# STM32L4x6_v1r1 register map
File version: 1.1
CPU: CM4 r0p1, little endian, MPU, FPU, 4 interrupt priority bits
Registers are 32-bit, read-write, reset 0x0 unless marked. A register's access mark holds for its fields unless they carry their own. Offsets are from the block's base; [hi:lo] are bit positions; {n}, {i} and the like mark numbered series; 'fields as' and 'values as' point back to an identical list.

## OPAMP — Operational amplifiers
Base 0x40007800
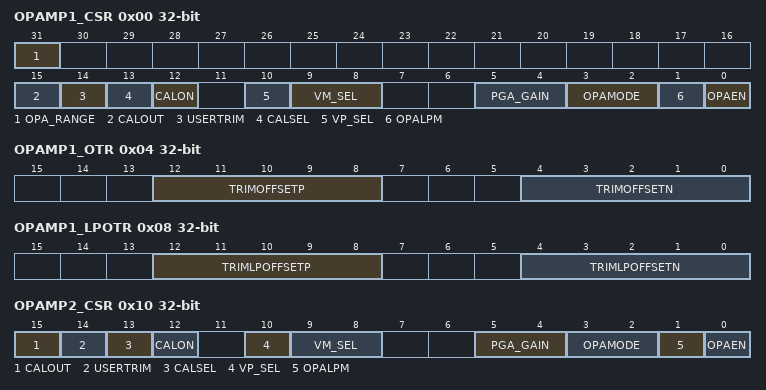
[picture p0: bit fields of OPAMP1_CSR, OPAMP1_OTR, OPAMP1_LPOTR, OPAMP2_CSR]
0x00 OPAMP1_CSR — OPAMP1 control/status register
  [31] OPA_RANGE — Operational amplifier power supply range for stability
  [15] CALOUT — Operational amplifier calibration output
  [14] USERTRIM — allows to switch from AOP offset trimmed values to AOP offset
  [13] CALSEL — Calibration selection
  [12] CALON — Calibration mode enabled
  [10] VP_SEL — Non inverted input selection
  [9:8] VM_SEL — Inverting input selection
  [5:4] PGA_GAIN — Operational amplifier Programmable amplifier gain value
  [3:2] OPAMODE — Operational amplifier PGA mode
  [1] OPALPM — Operational amplifier Low Power Mode
  [0] OPAEN — Operational amplifier Enable
0x04 OPAMP1_OTR — OPAMP1 offset trimming register in normal mode
  [12:8] TRIMOFFSETP — Trim for PMOS differential pairs
  [4:0] TRIMOFFSETN — Trim for NMOS differential pairs
0x08 OPAMP1_LPOTR — OPAMP1 offset trimming register in low-power mode
  [12:8] TRIMLPOFFSETP — Trim for PMOS differential pairs
  [4:0] TRIMLPOFFSETN — Trim for NMOS differential pairs
0x10 OPAMP2_CSR — OPAMP2 control/status register
  [15] CALOUT — Operational amplifier calibration output
  [14] USERTRIM — allows to switch from AOP offset trimmed values to AOP offset
  [13] CALSEL — Calibration selection
  [12] CALON — Calibration mode enabled
  [10] VP_SEL — Non inverted input selection
  [9:8] VM_SEL — Inverting input selection
  [5:4] PGA_GAIN — Operational amplifier Programmable amplifier gain value
  [3:2] OPAMODE — Operational amplifier PGA mode
  [1] OPALPM — Operational amplifier Low Power Mode
  [0] OPAEN — Operational amplifier Enable
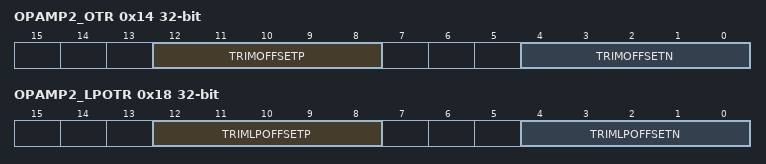
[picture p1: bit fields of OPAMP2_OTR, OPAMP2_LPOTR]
0x14 OPAMP2_OTR — OPAMP2 offset trimming register in normal mode
  fields as OPAMP1_OTR
0x18 OPAMP2_LPOTR — OPAMP2 offset trimming register in low-power mode
  fields as OPAMP1_LPOTR

## FMC — Flexible memory controller
Base 0xA0000000
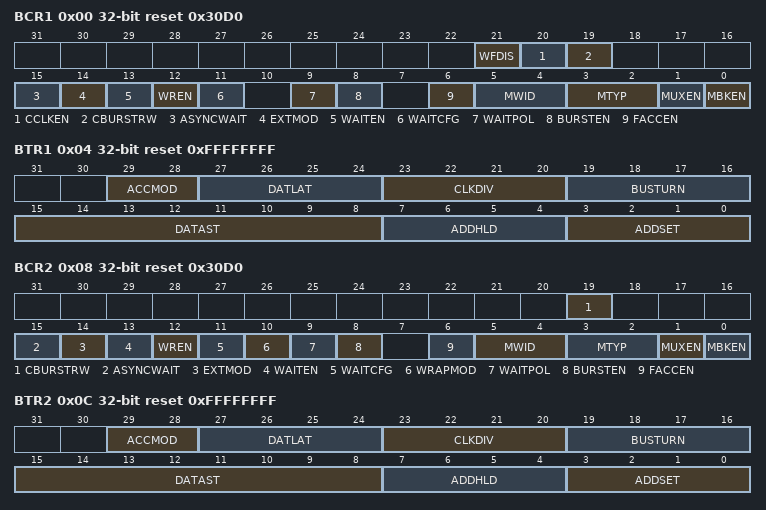
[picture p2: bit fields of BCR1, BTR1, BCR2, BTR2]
0x00 BCR1 reset 0x30D0 — SRAM/NOR-Flash chip-select control register 1
  [21] WFDIS — Write FIFO Disable
  [20] CCLKEN
  [19] CBURSTRW
  [15] ASYNCWAIT
  [14] EXTMOD
  [13] WAITEN
  [12] WREN
  [11] WAITCFG
  [9] WAITPOL
  [8] BURSTEN
  [6] FACCEN
  [5:4] MWID
  [3:2] MTYP
  [1] MUXEN
  [0] MBKEN
0x04 BTR1 reset 0xFFFFFFFF — SRAM/NOR-Flash chip-select timing register 1
  [29:28] ACCMOD, [27:24] DATLAT, [23:20] CLKDIV, [19:16] BUSTURN, [15:8] DATAST, [7:4] ADDHLD, [3:0] ADDSET
0x08 BCR2 reset 0x30D0 — SRAM/NOR-Flash chip-select control register 2
  [19] CBURSTRW, [15] ASYNCWAIT, [14] EXTMOD, [13] WAITEN, [12] WREN, [11] WAITCFG, [10] WRAPMOD, [9] WAITPOL, [8] BURSTEN, [6] FACCEN, [5:4] MWID, [3:2] MTYP, [1] MUXEN, [0] MBKEN
0x0C BTR2 reset 0xFFFFFFFF — SRAM/NOR-Flash chip-select timing register 2
  fields as BTR1
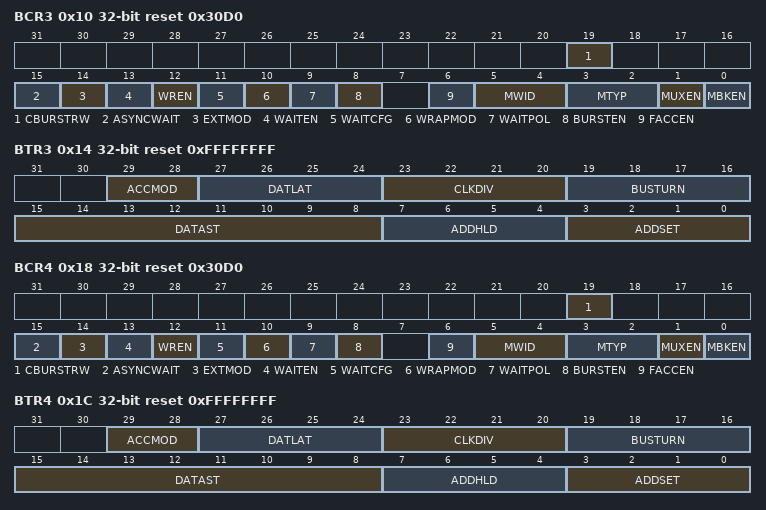
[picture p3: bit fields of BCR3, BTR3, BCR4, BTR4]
0x10 BCR3 reset 0x30D0 — SRAM/NOR-Flash chip-select control register 3
  fields as BCR2
0x14 BTR3 reset 0xFFFFFFFF — SRAM/NOR-Flash chip-select timing register 3
  fields as BTR1
0x18 BCR4 reset 0x30D0 — SRAM/NOR-Flash chip-select control register 4
  fields as BCR2
0x1C BTR4 reset 0xFFFFFFFF — SRAM/NOR-Flash chip-select timing register 4
  fields as BTR1
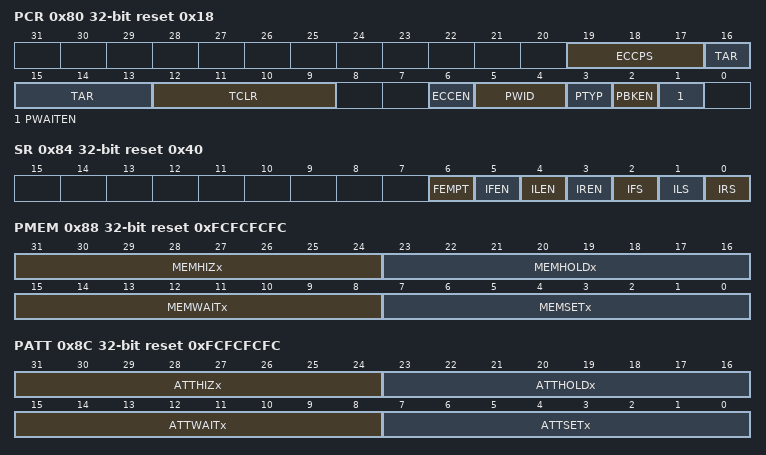
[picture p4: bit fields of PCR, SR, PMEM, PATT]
0x80 PCR reset 0x18 — PC Card/NAND Flash control register 3
  [19:17] ECCPS, [16:13] TAR, [12:9] TCLR, [6] ECCEN, [5:4] PWID, [3] PTYP, [2] PBKEN, [1] PWAITEN
0x84 SR access per field reset 0x40 — FIFO status and interrupt register 3
  [6] FEMPT ro, [5] IFEN rw, [4] ILEN rw, [3] IREN rw, [2] IFS rw, [1] ILS rw, [0] IRS rw
0x88 PMEM reset 0xFCFCFCFC — Common memory space timing register 3
  [31:24] MEMHIZx, [23:16] MEMHOLDx, [15:8] MEMWAITx, [7:0] MEMSETx
0x8C PATT reset 0xFCFCFCFC — Attribute memory space timing register 3
  [31:24] ATTHIZx, [23:16] ATTHOLDx, [15:8] ATTWAITx, [7:0] ATTSETx
0x94 ECCR ro — ECC result register 3
  [31:0] ECCx
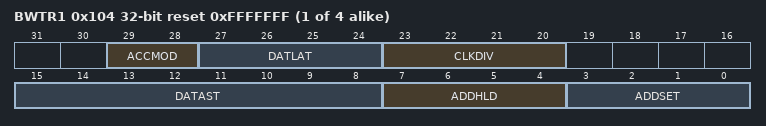
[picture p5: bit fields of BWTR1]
{0xFC+8i} BWTR{i} reset 0xFFFFFFF (i=1..4) — SRAM/NOR-Flash write timing registers {i}
  [29:28] ACCMOD, [27:24] DATLAT, [23:20] CLKDIV, [15:8] DATAST, [7:4] ADDHLD, [3:0] ADDSET
